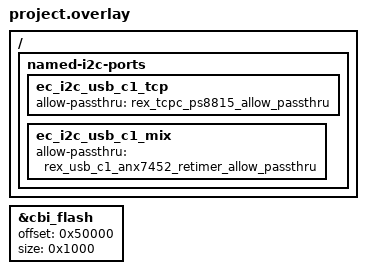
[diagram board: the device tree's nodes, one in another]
/* Copyright 2022 The ChromiumOS Authors
 * Use of this source code is governed by a BSD-style license that can be
 * found in the LICENSE file.
 */

#include <cros/cbi_flash.dtsi>

/* Rex program common DTSI includes */
#include "../battery.dtsi"
#include "../fan.dtsi"
#include "../generated.dtsi"
#include "../interrupts.dtsi"
#include "../keyboard.dtsi"
#include <program/rex/motionsense.dtsi>
#include "../power_signals.dtsi"
#include "../rex.dtsi"
#include "../temp_sensors.dtsi"
#include "../usbc.dtsi"

/* Rex project DTS includes */
#include "cbi.dtsi"
#include "i2c.dtsi"
#include "led_pins.dtsi"
#include "led_policy.dtsi"

&cbi_flash {
	/*
	 * CBI section size is 0x1000 bytes, the CBI portion lies at the end of
	 * EC_RO section. EC_RO section ends at 0x50000 byte which is the offset
	 */
	offset = <0x50000>;
	size = <0x1000>;
};

/ {
	named-i2c-ports {
		ec_i2c_usb_c1_tcp {
			allow-passthru = "rex_tcpc_ps8815_allow_passthru";
		};
		ec_i2c_usb_c1_mix {
			allow-passthru = "rex_usb_c1_anx7452_retimer_allow_passthru";
		};
	};
};
